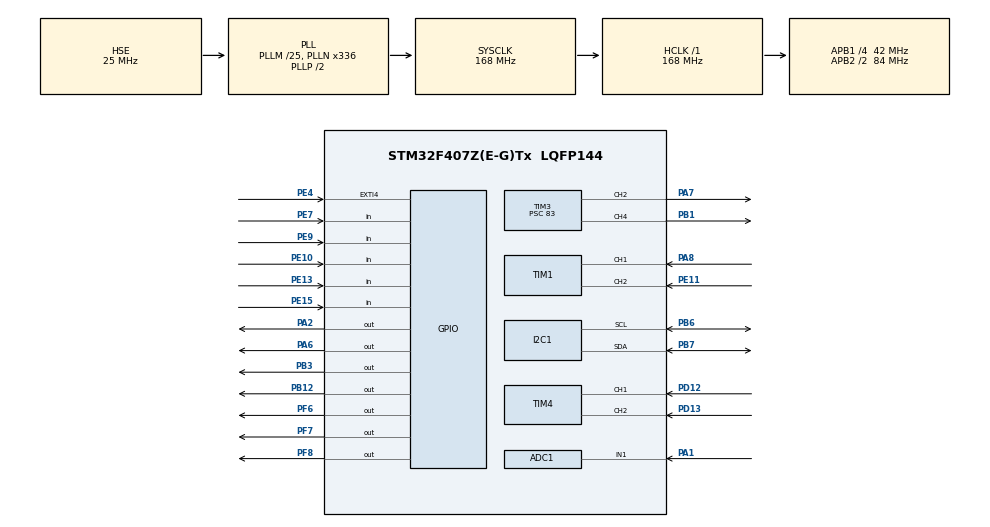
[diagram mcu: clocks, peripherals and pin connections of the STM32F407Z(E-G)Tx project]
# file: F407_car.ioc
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ADC1.Channel-0\#ChannelRegularConversion=ADC_CHANNEL_1
ADC1.ContinuousConvMode=DISABLE
ADC1.NbrOfConversionFlag=1
ADC1.Rank-0\#ChannelRegularConversion=1
ADC1.SamplingTime-0\#ChannelRegularConversion=ADC_SAMPLETIME_15CYCLES
ADC1.master=1
Dma.I2C1_RX.0.Direction=DMA_PERIPH_TO_MEMORY
Dma.I2C1_RX.0.FIFOMode=DMA_FIFOMODE_DISABLE
Dma.I2C1_RX.0.Instance=DMA1_Stream0
Dma.I2C1_RX.0.MemDataAlignment=DMA_MDATAALIGN_BYTE
Dma.I2C1_RX.0.MemInc=DMA_MINC_ENABLE
Dma.I2C1_RX.0.Mode=DMA_NORMAL
Dma.I2C1_RX.0.PeriphDataAlignment=DMA_PDATAALIGN_BYTE
Dma.I2C1_RX.0.PeriphInc=DMA_PINC_DISABLE
Dma.I2C1_RX.0.Priority=DMA_PRIORITY_HIGH
Dma.I2C1_TX.1.Direction=DMA_MEMORY_TO_PERIPH
Dma.I2C1_TX.1.FIFOMode=DMA_FIFOMODE_DISABLE
Dma.I2C1_TX.1.Instance=DMA1_Stream6
Dma.I2C1_TX.1.MemDataAlignment=DMA_MDATAALIGN_BYTE
Dma.I2C1_TX.1.MemInc=DMA_MINC_ENABLE
Dma.I2C1_TX.1.Mode=DMA_NORMAL
Dma.I2C1_TX.1.PeriphDataAlignment=DMA_PDATAALIGN_BYTE
Dma.I2C1_TX.1.PeriphInc=DMA_PINC_DISABLE
Dma.I2C1_TX.1.Priority=DMA_PRIORITY_HIGH
Dma.Request0=I2C1_RX
Dma.Request1=I2C1_TX
FREERTOS.Tasks01=defaultTask,-3,128,StartDefaultTask,Default,NULL,Dynamic,NULL,NULL
FREERTOS.configENABLE_FPU=1
FREERTOS.configUSE_TIMERS=0
I2C1.I2C_Mode=I2C_Fast
Mcu.Family=STM32F4
Mcu.Name=STM32F407Z(E-G)Tx
Mcu.Package=LQFP144
NVIC.DMA1_Stream0_IRQn=true\:5\:0\:false\:false\:true\:true\:false\:true\:true
NVIC.DMA1_Stream6_IRQn=true\:5\:0\:false\:false\:true\:true\:false\:true\:true
NVIC.EXTI4_IRQn=true\:5\:0\:false\:false\:true\:true\:true\:true\:true
NVIC.I2C1_EV_IRQn=true\:5\:0\:false\:false\:true\:true\:true\:true\:true
NVIC.PriorityGroup=NVIC_PRIORITYGROUP_4
NVIC.TIM6_DAC_IRQn=true\:6\:0\:true\:false\:true\:true\:true\:true\:true
PA1.Signal=ADCx_IN1
PA13.Mode=Serial_Wire
PA13.Signal=SYS_JTMS-SWDIO
PA14.Mode=Serial_Wire
PA14.Signal=SYS_JTCK-SWCLK
PA2.GPIO_Speed=GPIO_SPEED_FREQ_HIGH
PA2.PinState=GPIO_PIN_SET
PA2.Signal=GPIO_Output
PA6.GPIO_PuPd=GPIO_NOPULL
PA6.GPIO_Speed=GPIO_SPEED_FREQ_MEDIUM
PA6.PinState=GPIO_PIN_RESET
PA6.Signal=GPIO_Output
PA7.GPIO_Speed=GPIO_SPEED_FREQ_HIGH
PA7.Signal=S_TIM3_CH2
PA8.GPIO_PuPd=GPIO_PULLUP
PA8.GPIO_Speed=GPIO_SPEED_FREQ_VERY_HIGH
PA8.Signal=S_TIM1_CH1
PB1.GPIO_Speed=GPIO_SPEED_FREQ_HIGH
PB1.Signal=S_TIM3_CH4
PB12.GPIO_Speed=GPIO_SPEED_FREQ_HIGH
PB12.Signal=GPIO_Output
PB3.PinState=GPIO_PIN_RESET
PB3.Signal=GPIO_Output
PB6.GPIO_Pu=GPIO_PULLUP
PB6.Mode=I2C
PB6.Signal=I2C1_SCL
PB7.GPIO_Pu=GPIO_PULLUP
PB7.Mode=I2C
PB7.Signal=I2C1_SDA
PD12.GPIO_PuPd=GPIO_PULLUP
PD12.GPIO_Speed=GPIO_SPEED_FREQ_VERY_HIGH
PD12.Signal=S_TIM4_CH1
PD13.GPIO_PuPd=GPIO_PULLUP
PD13.GPIO_Speed=GPIO_SPEED_FREQ_VERY_HIGH
PD13.Signal=S_TIM4_CH2
PE10.GPIO_PuPd=GPIO_PULLUP
PE10.Signal=GPIO_Input
PE11.GPIO_PuPd=GPIO_PULLUP
PE11.GPIO_Speed=GPIO_SPEED_FREQ_VERY_HIGH
PE11.Signal=S_TIM1_CH2
PE13.GPIO_PuPd=GPIO_PULLUP
PE13.Signal=GPIO_Input
PE15.GPIO_PuPd=GPIO_PULLUP
PE15.Signal=GPIO_Input
PE4.GPIO_ModeDefaultEXTI=GPIO_MODE_IT_RISING_FALLING
PE4.GPIO_PuPd=GPIO_PULLUP
PE4.Signal=GPXTI4
PE7.GPIO_PuPd=GPIO_PULLUP
PE7.Signal=GPIO_Input
PE9.GPIO_PuPd=GPIO_PULLUP
PE9.Signal=GPIO_Input
PF6.GPIO_Speed=GPIO_SPEED_FREQ_HIGH
PF6.Signal=GPIO_Output
PF7.GPIO_Speed=GPIO_SPEED_FREQ_HIGH
PF7.Signal=GPIO_Output
PF8.GPIO_Speed=GPIO_SPEED_FREQ_HIGH
PF8.PinState=GPIO_PIN_RESET
PF8.Signal=GPIO_Output
PH0-OSC_IN.Mode=HSE-External-Oscillator
PH0-OSC_IN.Signal=RCC_OSC_IN
PH1-OSC_OUT.Mode=HSE-External-Oscillator
PH1-OSC_OUT.Signal=RCC_OSC_OUT
ProjectManager.HeapSize=0x200
ProjectManager.StackSize=0x400
ProjectManager.TargetToolchain=CMake
RCC.48MHZClocksFreq_Value=84000000
RCC.AHBFreq_Value=168000000
RCC.APB1CLKDivider=RCC_HCLK_DIV4
RCC.APB1Freq_Value=42000000
RCC.APB1TimFreq_Value=84000000
RCC.APB2CLKDivider=RCC_HCLK_DIV2
RCC.APB2Freq_Value=84000000
RCC.APB2TimFreq_Value=168000000
RCC.CortexFreq_Value=168000000
RCC.HCLKFreq_Value=168000000
RCC.HSE_VALUE=25000000
RCC.HSI_VALUE=16000000
RCC.LSE_VALUE=32768
RCC.PLLM=25
RCC.PLLN=336
RCC.PLLSourceVirtual=RCC_PLLSOURCE_HSE
RCC.SYSCLKFreq_VALUE=168000000
RCC.SYSCLKSource=RCC_SYSCLKSOURCE_PLLCLK
RCC.VCOOutputFreq_Value=336000000
SH.ADCx_IN1.0=ADC1_IN1,IN1
SH.S_TIM1_CH1.0=TIM1_CH1,Encoder_Interface
SH.S_TIM1_CH2.0=TIM1_CH2,Encoder_Interface
SH.S_TIM3_CH2.0=TIM3_CH2,PWM Generation2 CH2
SH.S_TIM3_CH4.0=TIM3_CH4,PWM Generation4 CH4
SH.S_TIM4_CH1.0=TIM4_CH1,Encoder_Interface
SH.S_TIM4_CH2.0=TIM4_CH2,Encoder_Interface
TIM1.EncoderMode=TIM_ENCODERMODE_TI12
TIM1.IC2Filter=8
TIM3.AutoReloadPreload=TIM_AUTORELOAD_PRELOAD_ENABLE
TIM3.Channel-PWM\ Generation2\ CH2=TIM_CHANNEL_2
TIM3.Channel-PWM\ Generation4\ CH4=TIM_CHANNEL_4
TIM3.ClockDivision=TIM_CLOCKDIVISION_DIV1
TIM3.Period=49
TIM3.Prescaler=83
TIM4.EncoderMode=TIM_ENCODERMODE_TI12
TIM4.IC2Filter=8
TIM6.Period=99
TIM6.Prescaler=8399
VP_FREERTOS_VS_CMSIS_V1.Mode=CMSIS_V1
VP_TIM3_VS_ClockSourceINT.Mode=Internal
VP_TIM6_VS_ClockSourceINT.Mode=Enable_Timer
board=custom

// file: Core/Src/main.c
/* USER CODE BEGIN Header */
/**
  ******************************************************************************
  * @file           : main.c
  * @brief          : Main program body
  ******************************************************************************
  * @attention
  *
  * Copyright (c) 2026 STMicroelectronics.
  * All rights reserved.
  *
  * This software is licensed under terms that can be found in the LICENSE file
  * in the root directory of this software component.
  * If no LICENSE file comes with this software, it is provided AS-IS.
  *
  ******************************************************************************
  */
/* USER CODE END Header */
#include "main.h"
#include "cmsis_os.h"
#include "adc.h"
#include "dma.h"
#include "i2c.h"
#include "tim.h"
#include "gpio.h"

/* USER CODE BEGIN Includes */
#include "bsp_motor.h"
#include "bsp_dwt.h"
#include "MPU6050.h"
//#include "speed_pid.h"
/* USER CODE END Includes */

void SystemClock_Config(void);
void MX_FREERTOS_Init(void);

int main(void)
{

  /* MCU Configuration--------------------------------------------------------*/

  /* Reset of all peripherals, Initializes the Flash interface and the Systick. */
  HAL_Init();

  /* Configure the system clock */
  SystemClock_Config();

  /* Initialize all configured peripherals */
  MX_GPIO_Init();
  MX_DMA_Init();
  MX_TIM3_Init();
  MX_TIM4_Init();
  MX_ADC1_Init();
  MX_TIM1_Init();
  MX_I2C1_Init();
  MX_TIM6_Init();
  /* USER CODE BEGIN 2 */
  BSP_DWT_Init();
  BSP_Motor_Init();
  //speed_pid_clear();
  /* USER CODE END 2 */

  /* Call init function for freertos objects (in cmsis_os2.c) */
  MX_FREERTOS_Init();

  /* Start scheduler */
  osKernelStart();

  /* We should never get here as control is now taken by the scheduler */

  /* Infinite loop */
  while (1)
  {

  }
}

void SystemClock_Config(void)
{
  RCC_OscInitTypeDef RCC_OscInitStruct = {0};
  RCC_ClkInitTypeDef RCC_ClkInitStruct = {0};

  /** Configure the main internal regulator output voltage
  */
  __HAL_RCC_PWR_CLK_ENABLE();
  __HAL_PWR_VOLTAGESCALING_CONFIG(PWR_REGULATOR_VOLTAGE_SCALE1);

  /** Initializes the RCC Oscillators according to the specified parameters
  * in the RCC_OscInitTypeDef structure.
  */
  RCC_OscInitStruct.OscillatorType = RCC_OSCILLATORTYPE_HSE;
  RCC_OscInitStruct.HSEState = RCC_HSE_ON;
  RCC_OscInitStruct.PLL.PLLState = RCC_PLL_ON;
  RCC_OscInitStruct.PLL.PLLSource = RCC_PLLSOURCE_HSE;
  RCC_OscInitStruct.PLL.PLLM = 25;
  RCC_OscInitStruct.PLL.PLLN = 336;
  RCC_OscInitStruct.PLL.PLLP = RCC_PLLP_DIV2;
  RCC_OscInitStruct.PLL.PLLQ = 4;
  if (HAL_RCC_OscConfig(&RCC_OscInitStruct) != HAL_OK)
  {
    Error_Handler();
  }

  /** Initializes the CPU, AHB and APB buses clocks
  */
  RCC_ClkInitStruct.ClockType = RCC_CLOCKTYPE_HCLK|RCC_CLOCKTYPE_SYSCLK
                              |RCC_CLOCKTYPE_PCLK1|RCC_CLOCKTYPE_PCLK2;
  RCC_ClkInitStruct.SYSCLKSource = RCC_SYSCLKSOURCE_PLLCLK;
  RCC_ClkInitStruct.AHBCLKDivider = RCC_SYSCLK_DIV1;
  RCC_ClkInitStruct.APB1CLKDivider = RCC_HCLK_DIV4;
  RCC_ClkInitStruct.APB2CLKDivider = RCC_HCLK_DIV2;

  if (HAL_RCC_ClockConfig(&RCC_ClkInitStruct, FLASH_LATENCY_5) != HAL_OK)
  {
    Error_Handler();
  }
}

void Error_Handler(void)
{
  __disable_irq();
  while (1)
  {
  }
}

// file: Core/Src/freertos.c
/* USER CODE BEGIN Header */
/**
  ******************************************************************************
  * File Name          : freertos.c
  * Description        : Code for freertos applications
  ******************************************************************************
  * @attention
  *
  * Copyright (c) 2026 STMicroelectronics.
  * All rights reserved.
  *
  * This software is licensed under terms that can be found in the LICENSE file
  * in the root directory of this software component.
  * If no LICENSE file comes with this software, it is provided AS-IS.
  *
  ******************************************************************************
  */
/* USER CODE END Header */

#include "FreeRTOS.h"
#include "task.h"
#include "main.h"
#include "cmsis_os.h"

/* USER CODE BEGIN Includes */
extern void MotorTask_Init();
extern void MPU6050ReadTask_Init();
extern void BalanceTask_Init();
extern void CarTask_Init();

/* USER CODE END Includes */

osThreadId defaultTaskHandle;

void StartDefaultTask(void const * argument);

void MX_FREERTOS_Init(void); /* (MISRA C 2004 rule 8.1) */

/* GetIdleTaskMemory prototype (linked to static allocation support) */
void vApplicationGetIdleTaskMemory( StaticTask_t **ppxIdleTaskTCBBuffer, StackType_t **ppxIdleTaskStackBuffer, uint32_t *pulIdleTaskStackSize );

/* USER CODE BEGIN GET_IDLE_TASK_MEMORY */
static StaticTask_t xIdleTaskTCBBuffer;
static StackType_t xIdleStack[configMINIMAL_STACK_SIZE];

void vApplicationGetIdleTaskMemory( StaticTask_t **ppxIdleTaskTCBBuffer, StackType_t **ppxIdleTaskStackBuffer, uint32_t *pulIdleTaskStackSize )
{
  *ppxIdleTaskTCBBuffer = &xIdleTaskTCBBuffer;
  *ppxIdleTaskStackBuffer = &xIdleStack[0];
  *pulIdleTaskStackSize = configMINIMAL_STACK_SIZE;
  /* place for user code */
}
/* USER CODE END GET_IDLE_TASK_MEMORY */

void MX_FREERTOS_Init(void) {

  /* Create the thread(s) */
  /* definition and creation of defaultTask */
  osThreadDef(defaultTask, StartDefaultTask, osPriorityIdle, 0, 128);
  defaultTaskHandle = osThreadCreate(osThread(defaultTask), NULL);

  /* USER CODE BEGIN RTOS_THREADS */
  /* add threads, ... */
  MPU6050ReadTask_Init();
  //MotorTask_Init();
  BalanceTask_Init();
  CarTask_Init();
  /* USER CODE END RTOS_THREADS */

}

void StartDefaultTask(void const * argument)
{
  for(;;)
  {
    osDelay(1);
  }
}
